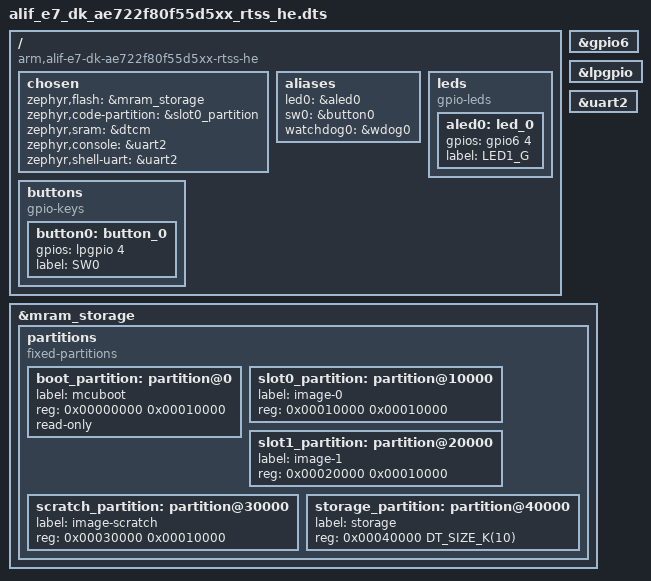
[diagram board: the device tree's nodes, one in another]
/* Copyright (c) 2025 Alif Semiconductor
 *
 * SPDX-License-Identifier: Apache-2.0
 */

/dts-v1/;

#include <alif/ensemble/e7/ae722f80f55d5xx.dtsi>
#include <alif/ensemble/common/ensemble_rtss_he.dtsi>
#include "../common/ensemble-pinctrl.dtsi"

/ {
	compatible = "arm,alif-e7-dk-ae722f80f55d5xx-rtss-he";
	#address-cells = <1>;
	#size-cells = <1>;

	chosen {
		zephyr,flash = &mram_storage;
		zephyr,code-partition = &slot0_partition;
		zephyr,sram = &dtcm;
		zephyr,console = &uart2;
		zephyr,shell-uart = &uart2;
	};

	aliases {
		led0 = &aled0;
		sw0 = &button0;
		watchdog0 = &wdog0;
	};

	leds {
		compatible = "gpio-leds";
		aled0: led_0 {
			gpios = <&gpio6 4 0>;
			label = "LED1_G";
		};
	};

	buttons {
		compatible = "gpio-keys";
		button0: button_0 {
			gpios = < &lpgpio 4 0 >;
			label = "SW0";
		};
	};
};

&gpio6 {
	status = "okay";
};

&lpgpio {
	status = "okay";
};

&uart2 {
	status = "okay";
};

&mram_storage {
	partitions {
		compatible = "fixed-partitions";
		#address-cells = <1>;
		#size-cells = <1>;
		boot_partition: partition@0 {
			label = "mcuboot";
			reg = <0x00000000 0x00010000>;
			read-only;
		};
		slot0_partition: partition@10000 {
			label = "image-0";
			reg = <0x00010000 0x00010000>;
		};
		slot1_partition: partition@20000 {
			label = "image-1";
			reg = <0x00020000 0x00010000>;
		};
		scratch_partition: partition@30000 {
			label = "image-scratch";
			reg = <0x00030000 0x00010000>;
		};
		storage_partition: partition@40000 {
			label = "storage";
			reg = <0x00040000 DT_SIZE_K(10)>;
		};
	};
};
